# f2838x_cm_cmsysctl_regs register map
Vendor: Texas Instruments
Peripheral module from a debugger description file (folder C2000).
Address unit: 16 bits
Registers are 32-bit, read-write, no defined reset value unless marked. A register's access mark holds for its fields unless they carry their own. Offsets are as the file gives them; lines under a group give offsets from that group; [hi:lo] are bit positions; {n}, {i} and the like mark numbered series; 'fields as' and 'values as' point back to an identical list; <NAME> marks a mode.

## CMSYSCTL_REGS — CMSYSCTL Registers
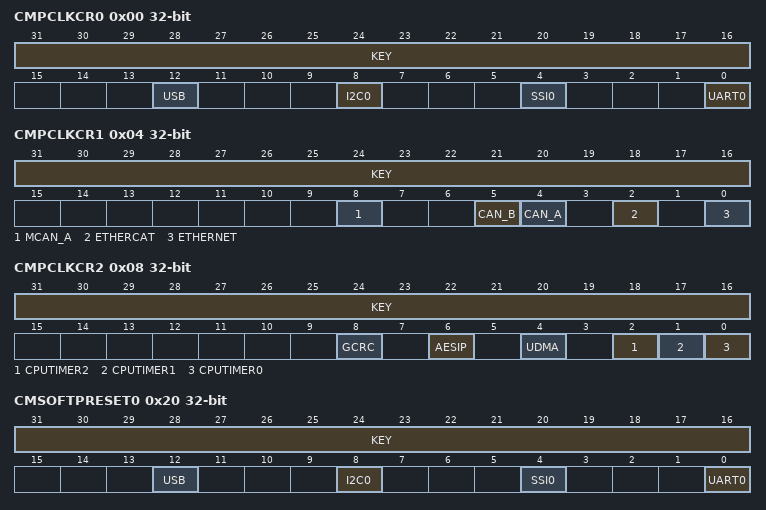
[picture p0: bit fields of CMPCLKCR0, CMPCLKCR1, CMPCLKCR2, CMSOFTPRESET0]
0x00 CMPCLKCR0 — CM Peripheral clock gating register 0.
  [31:16] KEY
  [12] USB — USB Clock gating Bit
  [8] I2C0 — I2C0 Clock gating Bit
  [4] SSI0 — SSI0 Clock gating Bit
  [0] UART0 — UART0 Clock gating Bit
0x04 CMPCLKCR1 — CM Peripheral clock gating register 1.
  [31:16] KEY
  [8] MCAN_A — MCAN_A Clock gating Bit
  [5] CAN_B — CAN_B Clock gating Bit
  [4] CAN_A — CAN_A Clock gating Bit
  [2] ETHERCAT — ETHERCAT Clock gating Bit
  [0] ETHERNET — ETHERNET Clock gating Bit
0x08 CMPCLKCR2 — CM Peripheral clock gating register 2.
  [31:16] KEY
  [8] GCRC — GCRC Clock gating Bit
  [6] AESIP — AESIP Clock gating Bit
  [4] UDMA — UDMA Clock gating Bit
  [2] CPUTIMER2 — CPUTIMER2 Clock gating Bit
  [1] CPUTIMER1 — CPUTIMER1 Clock gating Bit
  [0] CPUTIMER0 — CPUTIMER0 Clock gating Bit
0x20 CMSOFTPRESET0 — CM Software Peripheral Reset register 0
  [31:16] KEY
  [12] USB — USB Soft reset bit
  [8] I2C0 — I2C0 Soft reset bit
  [4] SSI0 — SSI0 Soft reset bit
  [0] UART0 — UART0 Soft reset bit
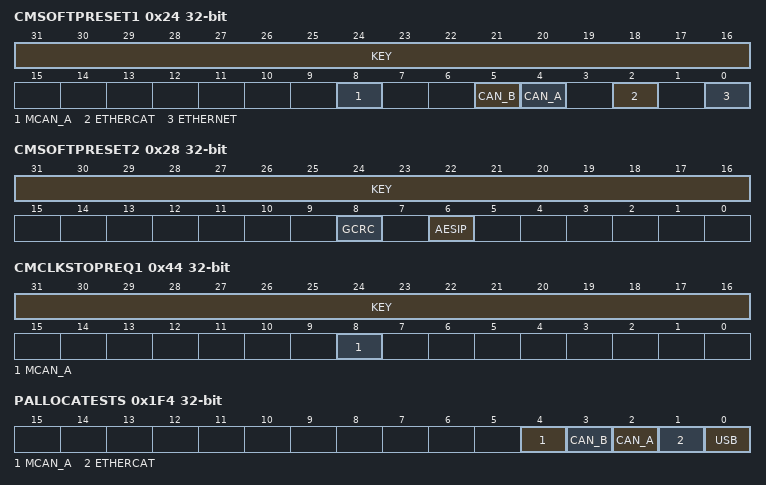
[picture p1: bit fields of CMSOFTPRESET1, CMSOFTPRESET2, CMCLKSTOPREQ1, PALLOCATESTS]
0x24 CMSOFTPRESET1 — CM Software Peripheral Reset register 1
  [31:16] KEY
  [8] MCAN_A — MCAN_A Soft reset bit
  [5] CAN_B — CAN_B Soft reset bit
  [4] CAN_A — CAN_A Soft reset bit
  [2] ETHERCAT — ETHERCAT Soft reset bit
  [0] ETHERNET — ETHERNET Soft reset bit
0x28 CMSOFTPRESET2 — CM Software Peripheral Reset register 2
  [31:16] KEY
  [8] GCRC — GCRC Soft reset bit
  [6] AESIP — AESIP Soft reset bit
0x40 CMCLKSTOPREQ0 — Peripheral Clock Stop Request Register 0
  [31:16] KEY
0x44 CMCLKSTOPREQ1 — Peripheral Clock Stop Request Register 1
  [31:16] KEY
  [8] MCAN_A — MCAN_A Clock Stop Request Bit
0x48 CMCLKSTOPREQ2 — Peripheral Clock Stop Request Register 2
  [31:16] KEY
0x60 CMCLKSTOPACK0 access not given — Peripheral Clock Stop Ackonwledge Register 0
0x64 CMCLKSTOPACK1 ro — Peripheral Clock Stop Ackonwledge Register 1
  [8] MCAN_A — MCAN_A Clock Stop Ack Bit
0x68 CMCLKSTOPACK2 access not given — Peripheral Clock Stop Ackonwledge Register 2
0xE0 MCANWAKESTATUS ro
  [0] WAKE — MCAN Wake Status
0xE4 MCANWAKESTATUSCLR — MCAN Wake Status Clear Register
  [0] WAKE — Cear bit for MCANWAKESTATUS.WAKE bit
0x100 CMECATCTL — CM etherCAT control register
  [0] I2CLOOPBACK — Loopback I2C port of etherCAT IP to CM I2C.
0x1F4 PALLOCATESTS ro — Status of PALLOCATE register.
  [4] MCAN_A — Status of PALLOCATE.MCAN_A bit
  [3] CAN_B — Status of PALLOCATE.CAN_B bit
  [2] CAN_A — Status of PALLOCATE.CAN_A bit
  [1] ETHERCAT — Status of PALLOCATE.ETHERCAT bit
  [0] USB — Status of PALLOCATE.USB bit
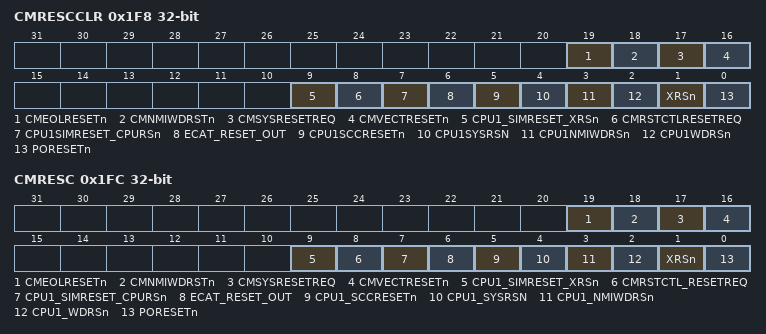
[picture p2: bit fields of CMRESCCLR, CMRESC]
0x1F8 CMRESCCLR — CM Reset Cause Status Clear Register
  [19] CMEOLRESETn — CMEOLRESETn status flag clear
  [18] CMNMIWDRSTn — CMNMIWDRSTn status flag clear
  [17] CMSYSRESETREQ — CMSYSRESETREQ status flag clear
  [16] CMVECTRESETn — CMVECTRESETn status flag clear
  [9] CPU1_SIMRESET_XRSn — CPU1_SIMRESET_XRSn status flag clear
  [8] CMRSTCTLRESETREQ — CMRSTCTLRESETREQ status flag clear
  [7] CPU1SIMRESET_CPURSn — CPU1SIMRESET_CPURSn status flag clear
  [6] ECAT_RESET_OUT — ECAT_RESET_OUT status flag clear
  [5] CPU1SCCRESETn — CPU1SCCRESETn status flag clear
  [4] CPU1SYSRSN — CPU1SYSRSN status flag clear
  [3] CPU1NMIWDRSn — CPU1NMIWDRSn status flag clear
  [2] CPU1WDRSn — CPU1WDRSn status flag clear
  [1] XRSn — XRSn status flag clear
  [0] PORESETn — PORESETn status flag clear
0x1FC CMRESC ro — CM Reset Cause Status Register
  [19] CMEOLRESETn — CMEOLRESETn caused the reset of CM
  [18] CMNMIWDRSTn — CMNMIWDRSTn caused the reset of CM
  [17] CMSYSRESETREQ — CMSYSRESETREQ caused the reset of CM
  [16] CMVECTRESETn — CMVECTRESETn caused the reset of CM
  [9] CPU1_SIMRESET_XRSn — CPU1_SIMRESET_XRSn caused the reset of CM
  [8] CMRSTCTL_RESETREQ — CMRSTCTL_RESETREQ caused the reset of CM
  [7] CPU1_SIMRESET_CPURSn — CPU1_SIMRESET_CPURSn caused the reset of CM
  [6] ECAT_RESET_OUT — ECAT_RESET_OUT caused the reset of CM
  [5] CPU1_SCCRESETn — CPU1_SCCRESETn caused the reset of CM
  [4] CPU1_SYSRSN — CPU1_SYSRSN caused the reset of CM
  [3] CPU1_NMIWDRSn — CPU1_NMIWDRSn caused the reset of CM
  [2] CPU1_WDRSn — CPU1_WDRSn caused the reset of CM
  [1] XRSn — XRSn caused the reset of CM
  [0] PORESETn — PORESETn caused the reset of CM
0x200 CMSYSCTLLOCK — Locks the configuration registers of CM System control
  [0] LOCK — Locks the configuration registers of CM System Control
